# MSP430G2X55 register map
Vendor: msp430gen; File version: v0.4.0-16-g4f822b9
Registers are 8-bit, read-write, reset 0x0 unless marked. A register's access mark holds for its fields unless they carry their own. Offsets are from the block's base; [hi:lo] are bit positions; {n}, {i} and the like mark numbered series.

## USCI_A0_SPI_MODE
Base 0x00000060
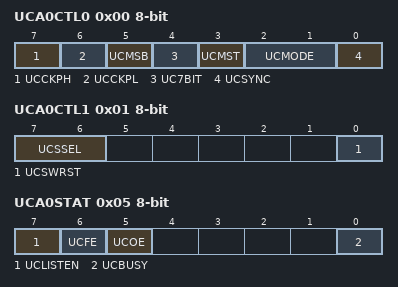
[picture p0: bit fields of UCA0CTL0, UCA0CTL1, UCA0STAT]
0x00 UCA0CTL0 — USCI A0 Control Register 0
  [7] UCCKPH — Sync. Mode: Clock Phase
  [6] UCCKPL — Sync. Mode: Clock Polarity
  [5] UCMSB — Sync. Mode: MSB first 0:LSB / 1:MSB
  [4] UC7BIT — Sync. Mode: Data Bits 0:8-bits / 1:7-bits
  [3] UCMST — Sync. Mode: Master Select
  [2:1] UCMODE — Sync. Mode: USCI Mode 1
    {v}=Sync. Mode: USCI Mode: {v} (v=0..3)
  [0] UCSYNC — Sync-Mode 0:UART-Mode / 1:SPI-Mode
0x01 UCA0CTL1 — USCI A0 Control Register 1
  [7:6] UCSSEL — USCI 1 Clock Source Select 1
    {v}=USCI 0 Clock Source: {v} (v=0..3)
  [0] UCSWRST — USCI Software Reset
0x02 UCA0BR0 — USCI A0 Baud Rate 0
  [7:0] UCA0BR0 — USCI A0 Baud Rate 0 register
0x03 UCA0BR1 — USCI A0 Baud Rate 1
  [7:0] UCA0BR1 — USCI A0 Baud Rate 1 register
0x05 UCA0STAT — USCI A0 Status Register
  [7] UCLISTEN — USCI Listen mode
  [6] UCFE — USCI Frame Error Flag
  [5] UCOE — USCI Overrun Error Flag
  [0] UCBUSY — USCI Busy Flag
0x06 UCA0RXBUF — USCI A0 Receive Buffer
  [7:0] UCA0RXBUF — USCI A0 Receive Buffer register
0x07 UCA0TXBUF — USCI A0 Transmit Buffer
  [7:0] UCA0TXBUF — USCI A0 Transmit Buffer register

## USCI_B0_I2C_MODE
Base 0x00000068
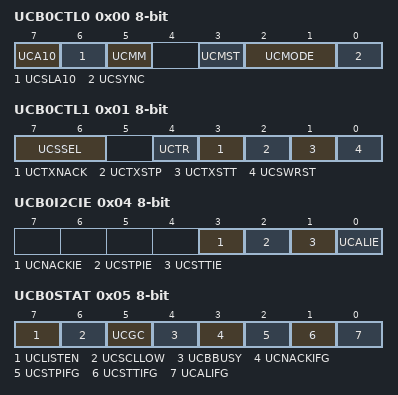
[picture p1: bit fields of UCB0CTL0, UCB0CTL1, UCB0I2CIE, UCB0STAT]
0x00 UCB0CTL0 — USCI B0 Control Register 0
  [7] UCA10 — 10-bit Address Mode
  [6] UCSLA10 — 10-bit Slave Address Mode
  [5] UCMM — Multi-Master Environment
  [3] UCMST — Sync. Mode: Master Select
  [2:1] UCMODE — Sync. Mode: USCI Mode 1
    {v}=Sync. Mode: USCI Mode: {v} (v=0..3)
  [0] UCSYNC — Sync-Mode 0:UART-Mode / 1:SPI-Mode
0x01 UCB0CTL1 — USCI B0 Control Register 1
  [7:6] UCSSEL — USCI 1 Clock Source Select 1
    {v}=USCI 0 Clock Source: {v} (v=0..3)
  [4] UCTR — Transmit/Receive Select/Flag
  [3] UCTXNACK — Transmit NACK
  [2] UCTXSTP — Transmit STOP
  [1] UCTXSTT — Transmit START
  [0] UCSWRST — USCI Software Reset
0x02 UCB0BR0 — USCI B0 Baud Rate 0
  [7:0] UCB0BR0 — USCI B0 Baud Rate 0 register
0x03 UCB0BR1 — USCI B0 Baud Rate 1
  [7:0] UCB0BR1 — USCI B0 Baud Rate 1 register
0x04 UCB0I2CIE — USCI B0 I2C Interrupt Enable Register
  [3] UCNACKIE — NACK Condition interrupt enable
  [2] UCSTPIE — STOP Condition interrupt enable
  [1] UCSTTIE — START Condition interrupt enable
  [0] UCALIE — Arbitration Lost interrupt enable
0x05 UCB0STAT — USCI B0 Status Register
  [7] UCLISTEN — USCI Listen mode
  [6] UCSCLLOW — SCL low
  [5] UCGC — General Call address received Flag
  [4] UCBBUSY — Bus Busy Flag
  [3] UCNACKIFG — NAK Condition interrupt Flag
  [2] UCSTPIFG — STOP Condition interrupt Flag
  [1] UCSTTIFG — START Condition interrupt Flag
  [0] UCALIFG — Arbitration Lost interrupt Flag
0x06 UCB0RXBUF — USCI B0 Receive Buffer
  [7:0] UCB0RXBUF — USCI B0 Receive Buffer register
0x07 UCB0TXBUF — USCI B0 Transmit Buffer
  [7:0] UCB0TXBUF — USCI B0 Transmit Buffer register
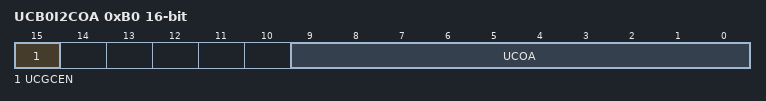
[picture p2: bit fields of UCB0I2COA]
0xB0 UCB0I2COA 16-bit — USCI B0 I2C Own Address
  [15] UCGCEN — I2C General Call enable
  [9:0] UCOA — I2C Own Address 0
0xB2 UCB0I2CSA 16-bit — USCI B0 I2C Slave Address
  [9:0] UCSA — I2C Slave Address 0

## USCI_B0_SPI_MODE
Base 0x00000068
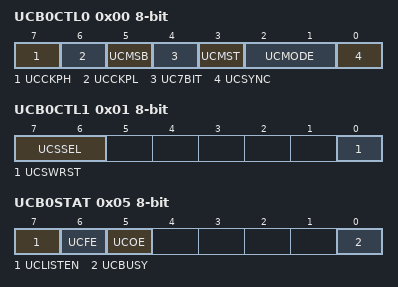
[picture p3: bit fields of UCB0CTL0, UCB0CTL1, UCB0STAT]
0x00 UCB0CTL0 — USCI B0 Control Register 0
  [7] UCCKPH — Sync. Mode: Clock Phase
  [6] UCCKPL — Sync. Mode: Clock Polarity
  [5] UCMSB — Sync. Mode: MSB first 0:LSB / 1:MSB
  [4] UC7BIT — Sync. Mode: Data Bits 0:8-bits / 1:7-bits
  [3] UCMST — Sync. Mode: Master Select
  [2:1] UCMODE — Sync. Mode: USCI Mode 1
    {v}=Sync. Mode: USCI Mode: {v} (v=0..3)
  [0] UCSYNC — Sync-Mode 0:UART-Mode / 1:SPI-Mode
0x01 UCB0CTL1 — USCI B0 Control Register 1
  [7:6] UCSSEL — USCI 1 Clock Source Select 1
    {v}=USCI 0 Clock Source: {v} (v=0..3)
  [0] UCSWRST — USCI Software Reset
0x02 UCB0BR0 — USCI B0 Baud Rate 0
  [7:0] UCB0BR0 — USCI B0 Baud Rate 0 register
0x03 UCB0BR1 — USCI B0 Baud Rate 1
  [7:0] UCB0BR1 — USCI B0 Baud Rate 1 register
0x05 UCB0STAT — USCI B0 Status Register
  [7] UCLISTEN — USCI Listen mode
  [6] UCFE — USCI Frame Error Flag
  [5] UCOE — USCI Overrun Error Flag
  [0] UCBUSY — USCI Busy Flag
0x06 UCB0RXBUF — USCI B0 Receive Buffer
  [7:0] UCB0RXBUF — USCI B0 Receive Buffer register
0x07 UCB0TXBUF — USCI B0 Transmit Buffer
  [7:0] UCB0TXBUF — USCI B0 Transmit Buffer register
